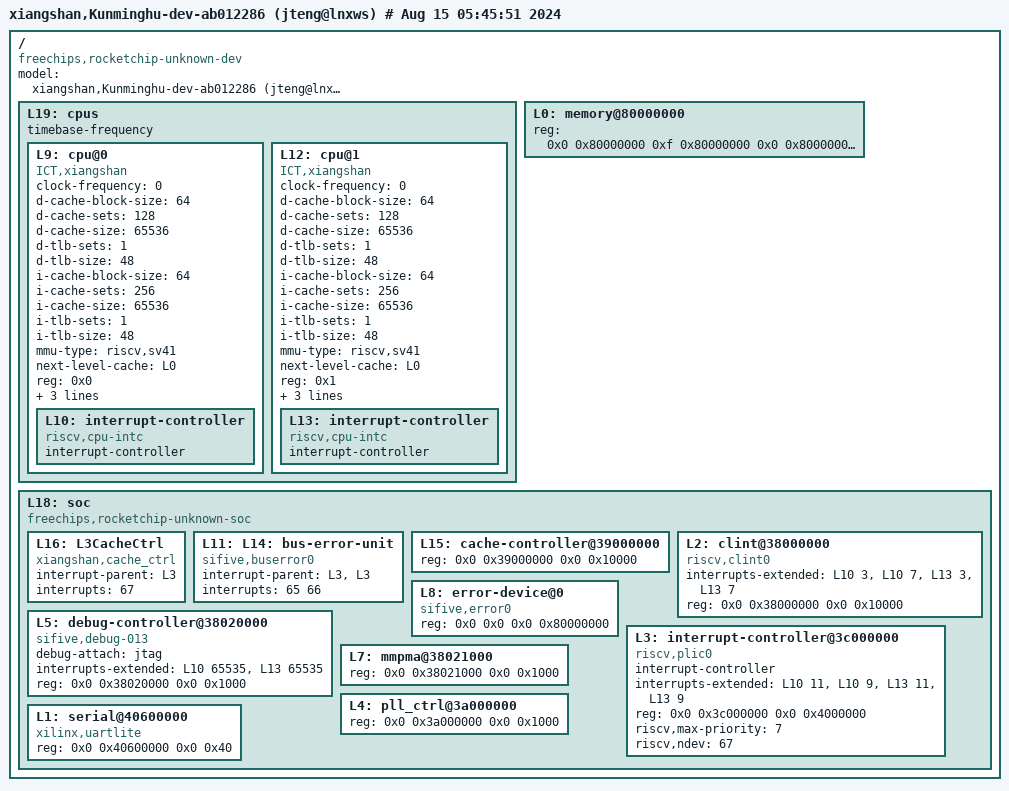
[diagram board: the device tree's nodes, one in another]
/dts-v1/;

/ {
	#address-cells = <2>;
	#size-cells = <2>;
	compatible = "freechips,rocketchip-unknown-dev";
	model = "xiangshan,Kunminghu-dev-ab012286 (jteng@lnxws) # Aug 15 05:45:51 2024";
	L19: cpus {
		#address-cells = <1>;
		#size-cells = <0>;
		timebase-frequency;
		L9: cpu@0 {
			clock-frequency = <0>;
			compatible = "ICT,xiangshan", "riscv";
			d-cache-block-size = <64>;
			d-cache-sets = <128>;
			d-cache-size = <65536>;
			d-tlb-sets = <1>;
			d-tlb-size = <48>;
			device_type = "cpu";
			i-cache-block-size = <64>;
			i-cache-sets = <256>;
			i-cache-size = <65536>;
			i-tlb-sets = <1>;
			i-tlb-size = <48>;
			mmu-type = "riscv,sv41";
			next-level-cache = <&L0>;
			reg = <0x0>;
			riscv,isa = "rv64imafdch";
			status = "okay";
			timebase-frequency = <1000000>;
			tlb-split;
			L10: interrupt-controller {
				#interrupt-cells = <1>;
				compatible = "riscv,cpu-intc";
				interrupt-controller;
			};
		};
		L12: cpu@1 {
			clock-frequency = <0>;
			compatible = "ICT,xiangshan", "riscv";
			d-cache-block-size = <64>;
			d-cache-sets = <128>;
			d-cache-size = <65536>;
			d-tlb-sets = <1>;
			d-tlb-size = <48>;
			device_type = "cpu";
			i-cache-block-size = <64>;
			i-cache-sets = <256>;
			i-cache-size = <65536>;
			i-tlb-sets = <1>;
			i-tlb-size = <48>;
			mmu-type = "riscv,sv41";
			next-level-cache = <&L0>;
			reg = <0x1>;
			riscv,isa = "rv64imafdch";
			status = "okay";
			timebase-frequency = <1000000>;
			tlb-split;
			L13: interrupt-controller {
				#interrupt-cells = <1>;
				compatible = "riscv,cpu-intc";
				interrupt-controller;
			};
		};
	};
	L0: memory@80000000 {
		device_type = "memory";
		reg = <0x0 0x80000000 0xf 0x80000000 0x0 0x80000000 0xf 0x80000000>;
	};
	L18: soc {
		#address-cells = <2>;
		#size-cells = <2>;
		compatible = "freechips,rocketchip-unknown-soc", "simple-bus";
		ranges;
		L16: L3CacheCtrl {
			compatible = "xiangshan,cache_ctrl";
			interrupt-parent = <&L3>;
			interrupts = <67>;
		};
		L11: L14: bus-error-unit {
			compatible = "sifive,buserror0", "sifive,buserror0";
			interrupt-parent = <&L3 &L3>;
			interrupts = <65 66>;
		};
		L15: cache-controller@39000000 {
			reg = <0x0 0x39000000 0x0 0x10000>;
			reg-names = "control";
		};
		L2: clint@38000000 {
			compatible = "riscv,clint0";
			interrupts-extended = <&L10 3 &L10 7 &L13 3 &L13 7>;
			reg = <0x0 0x38000000 0x0 0x10000>;
			reg-names = "control";
		};
		L5: debug-controller@38020000 {
			compatible = "sifive,debug-013", "riscv,debug-013";
			debug-attach = "jtag";
			interrupts-extended = <&L10 65535 &L13 65535>;
			reg = <0x0 0x38020000 0x0 0x1000>;
			reg-names = "control";
		};
		L8: error-device@0 {
			compatible = "sifive,error0";
			reg = <0x0 0x0 0x0 0x80000000>;
		};
		L3: interrupt-controller@3c000000 {
			#interrupt-cells = <1>;
			compatible = "riscv,plic0";
			interrupt-controller;
			interrupts-extended = <&L10 11 &L10 9 &L13 11 &L13 9>;
			reg = <0x0 0x3c000000 0x0 0x4000000>;
			reg-names = "control";
			riscv,max-priority = <7>;
			riscv,ndev = <67>;
		};
		L7: mmpma@38021000 {
			reg = <0x0 0x38021000 0x0 0x1000>;
			reg-names = "control";
		};
		L4: pll_ctrl@3a000000 {
			reg = <0x0 0x3a000000 0x0 0x1000>;
			reg-names = "control";
		};
		L1: serial@40600000 {
			compatible = "xilinx,uartlite";
			reg = <0x0 0x40600000 0x0 0x40>;
		};
	};
};
